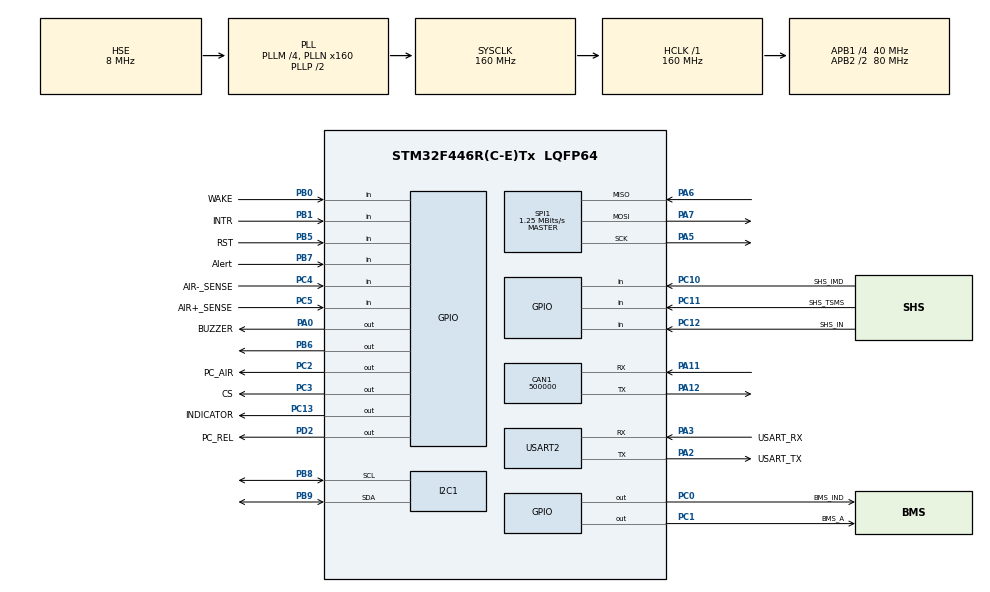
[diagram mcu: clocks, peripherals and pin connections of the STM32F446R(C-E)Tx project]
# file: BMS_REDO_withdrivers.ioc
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CAN1.BS1=CAN_BS1_2TQ
CAN1.BS2=CAN_BS2_2TQ
CAN1.CalculateBaudRate=500000
CAN1.CalculateTimeBit=2000
CAN1.CalculateTimeQuantum=400.0
Mcu.Family=STM32F4
Mcu.Name=STM32F446R(C-E)Tx
Mcu.Package=LQFP64
NVIC.CAN1_RX0_IRQn=true\:0\:0\:false\:false\:true\:true\:true\:true
NVIC.PriorityGroup=NVIC_PRIORITYGROUP_4
NVIC.TIM1_UP_TIM10_IRQn=true\:15\:0\:false\:false\:true\:false\:true\:true
NVIC.TimeBase=TIM1_UP_TIM10_IRQn
NVIC.TimeBaseIP=TIM1
PA0-WKUP.GPIO_Label=BUZZER
PA0-WKUP.GPIO_Speed=GPIO_SPEED_FREQ_VERY_HIGH
PA0-WKUP.PinState=GPIO_PIN_SET
PA0-WKUP.Signal=GPIO_Output
PA11.Mode=CAN_Activate
PA11.Signal=CAN1_RX
PA12.Mode=CAN_Activate
PA12.Signal=CAN1_TX
PA13.GPIO_Label=TMS
PA13.Mode=Serial_Wire
PA13.Signal=SYS_JTMS-SWDIO
PA14.GPIO_Label=TCK
PA14.Mode=Serial_Wire
PA14.Signal=SYS_JTCK-SWCLK
PA2.GPIO_Label=USART_TX
PA2.Mode=Asynchronous
PA2.Signal=USART2_TX
PA3.GPIO_Label=USART_RX
PA3.Mode=Asynchronous
PA3.Signal=USART2_RX
PA5.Mode=Full_Duplex_Master
PA5.Signal=SPI1_SCK
PA6.Mode=Full_Duplex_Master
PA6.Signal=SPI1_MISO
PA7.Mode=Full_Duplex_Master
PA7.Signal=SPI1_MOSI
PB0.GPIO_Label=WAKE
PB0.Signal=GPIO_Input
PB1.GPIO_Label=INTR
PB1.Signal=GPIO_Input
PB3.GPIO_Label=SWO
PB3.Signal=SYS_JTDO-SWO
PB5.GPIO_Label=RST
PB5.Signal=GPIO_Input
PB6.GPIO_PuPd=GPIO_NOPULL
PB6.GPIO_Speed=GPIO_SPEED_FREQ_VERY_HIGH
PB6.PinState=GPIO_PIN_SET
PB6.Signal=GPIO_Output
PB7.GPIO_Label=Alert
PB7.Signal=GPIO_Input
PB8.Mode=I2C
PB8.Signal=I2C1_SCL
PB9.Mode=I2C
PB9.Signal=I2C1_SDA
PC0.GPIO_Label=BMS_IND
PC0.Signal=GPIO_Output
PC1.GPIO_Label=BMS_A
PC1.Signal=GPIO_Output
PC10.GPIO_Label=SHS_IMD
PC10.Signal=GPIO_Input
PC11.GPIO_Label=SHS_TSMS
PC11.Signal=GPIO_Input
PC12.GPIO_Label=SHS_IN
PC12.Signal=GPIO_Input
PC13.GPIO_Label=INDICATOR
PC13.Signal=GPIO_Output
PC14-OSC32_IN.Mode=LSE-External-Oscillator
PC14-OSC32_IN.Signal=RCC_OSC32_IN
PC15-OSC32_OUT.Mode=LSE-External-Oscillator
PC15-OSC32_OUT.Signal=RCC_OSC32_OUT
PC2.GPIO_Label=PC_AIR
PC2.Signal=GPIO_Output
PC3.GPIO_Label=CS
PC3.GPIO_PuPd=GPIO_NOPULL
PC3.GPIO_Speed=GPIO_SPEED_FREQ_MEDIUM
PC3.PinState=GPIO_PIN_SET
PC3.Signal=GPIO_Output
PC4.GPIO_Label=AIR-_SENSE
PC4.Signal=GPIO_Input
PC5.GPIO_Label=AIR+_SENSE
PC5.Signal=GPIO_Input
PD2.GPIO_Label=PC_REL
PD2.Signal=GPIO_Output
PH0-OSC_IN.Mode=HSE-External-Oscillator
PH0-OSC_IN.Signal=RCC_OSC_IN
PH1-OSC_OUT.Mode=HSE-External-Oscillator
PH1-OSC_OUT.Signal=RCC_OSC_OUT
ProjectManager.HeapSize=0x200
ProjectManager.StackSize=0x400
ProjectManager.TargetToolchain=STM32CubeIDE
RCC.48MHZClocksFreq_Value=84000000
RCC.AHBFreq_Value=160000000
RCC.APB1CLKDivider=RCC_HCLK_DIV4
RCC.APB1Freq_Value=40000000
RCC.APB1TimFreq_Value=80000000
RCC.APB2CLKDivider=RCC_HCLK_DIV2
RCC.APB2Freq_Value=80000000
RCC.APB2TimFreq_Value=160000000
RCC.CortexFreq_Value=160000000
RCC.FLatency-AdvancedSettings=FLASH_LATENCY_5
RCC.HCLKFreq_Value=160000000
RCC.HSE_VALUE=8000000
RCC.HSI_VALUE=16000000
RCC.PLLM=4
RCC.PLLN=160
RCC.PLLSourceVirtual=RCC_PLLSOURCE_HSE
RCC.SYSCLKFreq_VALUE=160000000
RCC.SYSCLKSource=RCC_SYSCLKSOURCE_PLLCLK
RCC.USBFreq_Value=160000000
RCC.VCOOutputFreq_Value=320000000
SPI1.BaudRatePrescaler=SPI_BAUDRATEPRESCALER_64
SPI1.CLKPhase=SPI_PHASE_1EDGE
SPI1.CLKPolarity=SPI_POLARITY_LOW
SPI1.CalculateBaudRate=1.25 MBits/s
SPI1.Direction=SPI_DIRECTION_2LINES
SPI1.Mode=SPI_MODE_MASTER
SPI1.VirtualType=VM_MASTER
USART2.Parity=PARITY_NONE
USART2.VirtualMode=VM_ASYNC
VP_SYS_VS_tim1.Mode=TIM1
board=NUCLEO-F446RE

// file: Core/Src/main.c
/* USER CODE BEGIN Header */
/**
  ******************************************************************************
  * @file           : main.c
  * @brief          : Main program body
  ******************************************************************************
  * @attention
  *
  * Copyright (c) 2024 STMicroelectronics.
  * All rights reserved.
  *
  * This software is licensed under terms that can be found in the LICENSE file
  * in the root directory of this software component.
  * If no LICENSE file comes with this software, it is provided AS-IS.
  *
  ******************************************************************************
  */
/* USER CODE END Header */
#include "main.h"

CAN_HandleTypeDef hcan1;

I2C_HandleTypeDef hi2c1;

SPI_HandleTypeDef hspi1;

UART_HandleTypeDef huart2;

void SystemClock_Config(void);
static void MX_GPIO_Init(void);
static void MX_USART2_UART_Init(void);
static void MX_SPI1_Init(void);
static void MX_CAN1_Init(void);
static void MX_I2C1_Init(void);

int main(void)
{

  /* MCU Configuration--------------------------------------------------------*/

  /* Reset of all peripherals, Initializes the Flash interface and the Systick. */
  HAL_Init();

  /* Configure the system clock */
  SystemClock_Config();

  /* Initialize all configured peripherals */
  MX_GPIO_Init();
  MX_USART2_UART_Init();
  MX_SPI1_Init();
  MX_CAN1_Init();
  MX_I2C1_Init();
  /* USER CODE BEGIN 2 */

  FEB_Main_Setup();

  /* USER CODE END 2 */

  /* Infinite loop */
  while (1)
  {

    /* USER CODE BEGIN 3 */
	  FEB_Task_ADBMS();
	  FEB_Task_SM();
	  FEB_Task_Charge();
	  FEB_Task_Balance();
	  FEB_Task_IVT();
	  FEB_Task_CAN();
	  FEB_Task_UART();
  }
  /* USER CODE END 3 */
}

void SystemClock_Config(void)
{
  RCC_OscInitTypeDef RCC_OscInitStruct = {0};
  RCC_ClkInitTypeDef RCC_ClkInitStruct = {0};

  /** Configure the main internal regulator output voltage
  */
  __HAL_RCC_PWR_CLK_ENABLE();
  __HAL_PWR_VOLTAGESCALING_CONFIG(PWR_REGULATOR_VOLTAGE_SCALE1);

  /** Initializes the RCC Oscillators according to the specified parameters
  * in the RCC_OscInitTypeDef structure.
  */
  RCC_OscInitStruct.OscillatorType = RCC_OSCILLATORTYPE_HSE;
  RCC_OscInitStruct.HSEState = RCC_HSE_ON;
  RCC_OscInitStruct.PLL.PLLState = RCC_PLL_ON;
  RCC_OscInitStruct.PLL.PLLSource = RCC_PLLSOURCE_HSE;
  RCC_OscInitStruct.PLL.PLLM = 4;
  RCC_OscInitStruct.PLL.PLLN = 160;
  RCC_OscInitStruct.PLL.PLLP = RCC_PLLP_DIV2;
  RCC_OscInitStruct.PLL.PLLQ = 2;
  RCC_OscInitStruct.PLL.PLLR = 2;
  if (HAL_RCC_OscConfig(&RCC_OscInitStruct) != HAL_OK)
  {
    Error_Handler();
  }

  /** Initializes the CPU, AHB and APB buses clocks
  */
  RCC_ClkInitStruct.ClockType = RCC_CLOCKTYPE_HCLK|RCC_CLOCKTYPE_SYSCLK
                              |RCC_CLOCKTYPE_PCLK1|RCC_CLOCKTYPE_PCLK2;
  RCC_ClkInitStruct.SYSCLKSource = RCC_SYSCLKSOURCE_PLLCLK;
  RCC_ClkInitStruct.AHBCLKDivider = RCC_SYSCLK_DIV1;
  RCC_ClkInitStruct.APB1CLKDivider = RCC_HCLK_DIV4;
  RCC_ClkInitStruct.APB2CLKDivider = RCC_HCLK_DIV2;

  if (HAL_RCC_ClockConfig(&RCC_ClkInitStruct, FLASH_LATENCY_5) != HAL_OK)
  {
    Error_Handler();
  }
}

static void MX_CAN1_Init(void)
{

  hcan1.Instance = CAN1;
  hcan1.Init.Prescaler = 16;
  hcan1.Init.Mode = CAN_MODE_NORMAL;
  hcan1.Init.SyncJumpWidth = CAN_SJW_1TQ;
  hcan1.Init.TimeSeg1 = CAN_BS1_2TQ;
  hcan1.Init.TimeSeg2 = CAN_BS2_2TQ;
  hcan1.Init.TimeTriggeredMode = DISABLE;
  hcan1.Init.AutoBusOff = DISABLE;
  hcan1.Init.AutoWakeUp = DISABLE;
  hcan1.Init.AutoRetransmission = DISABLE;
  hcan1.Init.ReceiveFifoLocked = DISABLE;
  hcan1.Init.TransmitFifoPriority = DISABLE;
  if (HAL_CAN_Init(&hcan1) != HAL_OK)
  {
    Error_Handler();
  }

}

static void MX_I2C1_Init(void)
{

  hi2c1.Instance = I2C1;
  hi2c1.Init.ClockSpeed = 100000;
  hi2c1.Init.DutyCycle = I2C_DUTYCYCLE_2;
  hi2c1.Init.OwnAddress1 = 0;
  hi2c1.Init.AddressingMode = I2C_ADDRESSINGMODE_7BIT;
  hi2c1.Init.DualAddressMode = I2C_DUALADDRESS_DISABLE;
  hi2c1.Init.OwnAddress2 = 0;
  hi2c1.Init.GeneralCallMode = I2C_GENERALCALL_DISABLE;
  hi2c1.Init.NoStretchMode = I2C_NOSTRETCH_DISABLE;
  if (HAL_I2C_Init(&hi2c1) != HAL_OK)
  {
    Error_Handler();
  }

}

static void MX_SPI1_Init(void)
{

  /* SPI1 parameter configuration*/
  hspi1.Instance = SPI1;
  hspi1.Init.Mode = SPI_MODE_MASTER;
  hspi1.Init.Direction = SPI_DIRECTION_2LINES;
  hspi1.Init.DataSize = SPI_DATASIZE_8BIT;
  hspi1.Init.CLKPolarity = SPI_POLARITY_LOW;
  hspi1.Init.CLKPhase = SPI_PHASE_1EDGE;
  hspi1.Init.NSS = SPI_NSS_SOFT;
  hspi1.Init.BaudRatePrescaler = SPI_BAUDRATEPRESCALER_64;
  hspi1.Init.FirstBit = SPI_FIRSTBIT_MSB;
  hspi1.Init.TIMode = SPI_TIMODE_DISABLE;
  hspi1.Init.CRCCalculation = SPI_CRCCALCULATION_DISABLE;
  hspi1.Init.CRCPolynomial = 10;
  if (HAL_SPI_Init(&hspi1) != HAL_OK)
  {
    Error_Handler();
  }

}

static void MX_USART2_UART_Init(void)
{

  huart2.Instance = USART2;
  huart2.Init.BaudRate = 115200;
  huart2.Init.WordLength = UART_WORDLENGTH_8B;
  huart2.Init.StopBits = UART_STOPBITS_1;
  huart2.Init.Parity = UART_PARITY_NONE;
  huart2.Init.Mode = UART_MODE_TX_RX;
  huart2.Init.HwFlowCtl = UART_HWCONTROL_NONE;
  huart2.Init.OverSampling = UART_OVERSAMPLING_16;
  if (HAL_UART_Init(&huart2) != HAL_OK)
  {
    Error_Handler();
  }

}

static void MX_GPIO_Init(void)
{
  GPIO_InitTypeDef GPIO_InitStruct = {0};

  /* GPIO Ports Clock Enable */
  __HAL_RCC_GPIOC_CLK_ENABLE();
  __HAL_RCC_GPIOH_CLK_ENABLE();
  __HAL_RCC_GPIOA_CLK_ENABLE();
  __HAL_RCC_GPIOB_CLK_ENABLE();
  __HAL_RCC_GPIOD_CLK_ENABLE();

  /*Configure GPIO pin Output Level */
  HAL_GPIO_WritePin(GPIOC, INDICATOR_Pin|BMS_IND_Pin|BMS_A_Pin|PC_AIR_Pin, GPIO_PIN_RESET);

  /*Configure GPIO pin Output Level */
  HAL_GPIO_WritePin(CS_GPIO_Port, CS_Pin, GPIO_PIN_SET);

  /*Configure GPIO pin Output Level */
  HAL_GPIO_WritePin(BUZZER_GPIO_Port, BUZZER_Pin, GPIO_PIN_SET);

  /*Configure GPIO pin Output Level */
  HAL_GPIO_WritePin(PC_REL_GPIO_Port, PC_REL_Pin, GPIO_PIN_RESET);

  /*Configure GPIO pin Output Level */
  HAL_GPIO_WritePin(GPIOB, GPIO_PIN_6, GPIO_PIN_SET);

  /*Configure GPIO pins : INDICATOR_Pin BMS_IND_Pin BMS_A_Pin PC_AIR_Pin */
  GPIO_InitStruct.Pin = INDICATOR_Pin|BMS_IND_Pin|BMS_A_Pin|PC_AIR_Pin;
  GPIO_InitStruct.Mode = GPIO_MODE_OUTPUT_PP;
  GPIO_InitStruct.Pull = GPIO_NOPULL;
  GPIO_InitStruct.Speed = GPIO_SPEED_FREQ_LOW;
  HAL_GPIO_Init(GPIOC, &GPIO_InitStruct);

  /*Configure GPIO pin : CS_Pin */
  GPIO_InitStruct.Pin = CS_Pin;
  GPIO_InitStruct.Mode = GPIO_MODE_OUTPUT_PP;
  GPIO_InitStruct.Pull = GPIO_NOPULL;
  GPIO_InitStruct.Speed = GPIO_SPEED_FREQ_MEDIUM;
  HAL_GPIO_Init(CS_GPIO_Port, &GPIO_InitStruct);

  /*Configure GPIO pin : BUZZER_Pin */
  GPIO_InitStruct.Pin = BUZZER_Pin;
  GPIO_InitStruct.Mode = GPIO_MODE_OUTPUT_PP;
  GPIO_InitStruct.Pull = GPIO_NOPULL;
  GPIO_InitStruct.Speed = GPIO_SPEED_FREQ_VERY_HIGH;
  HAL_GPIO_Init(BUZZER_GPIO_Port, &GPIO_InitStruct);

  /*Configure GPIO pins : AIR__SENSE_Pin AIR__SENSEC5_Pin SHS_IMD_Pin SHS_TSMS_Pin
                           SHS_IN_Pin */
  GPIO_InitStruct.Pin = AIR__SENSE_Pin|AIR__SENSEC5_Pin|SHS_IMD_Pin|SHS_TSMS_Pin
                          |SHS_IN_Pin;
  GPIO_InitStruct.Mode = GPIO_MODE_INPUT;
  GPIO_InitStruct.Pull = GPIO_NOPULL;
  HAL_GPIO_Init(GPIOC, &GPIO_InitStruct);

  /*Configure GPIO pins : WAKE_Pin INTR_Pin RST_Pin Alert_Pin */
  GPIO_InitStruct.Pin = WAKE_Pin|INTR_Pin|RST_Pin|Alert_Pin;
  GPIO_InitStruct.Mode = GPIO_MODE_INPUT;
  GPIO_InitStruct.Pull = GPIO_NOPULL;
  HAL_GPIO_Init(GPIOB, &GPIO_InitStruct);

  /*Configure GPIO pin : PC_REL_Pin */
  GPIO_InitStruct.Pin = PC_REL_Pin;
  GPIO_InitStruct.Mode = GPIO_MODE_OUTPUT_PP;
  GPIO_InitStruct.Pull = GPIO_NOPULL;
  GPIO_InitStruct.Speed = GPIO_SPEED_FREQ_LOW;
  HAL_GPIO_Init(PC_REL_GPIO_Port, &GPIO_InitStruct);

  /*Configure GPIO pin : PB6 */
  GPIO_InitStruct.Pin = GPIO_PIN_6;
  GPIO_InitStruct.Mode = GPIO_MODE_OUTPUT_PP;
  GPIO_InitStruct.Pull = GPIO_NOPULL;
  GPIO_InitStruct.Speed = GPIO_SPEED_FREQ_VERY_HIGH;
  HAL_GPIO_Init(GPIOB, &GPIO_InitStruct);

}

void HAL_TIM_PeriodElapsedCallback(TIM_HandleTypeDef *htim)
{
  if (htim->Instance == TIM1) {
    HAL_IncTick();
  }
}

void Error_Handler(void)
{
  __disable_irq();
  while (1)
  {
  }
}
